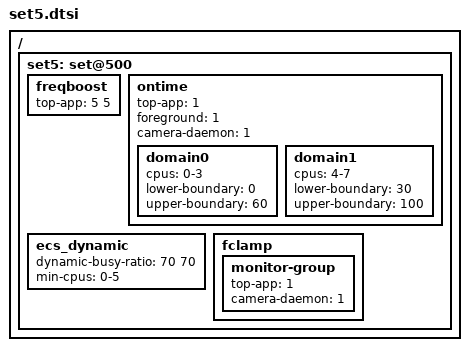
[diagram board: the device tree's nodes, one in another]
/ {
	/* camera mode - default */
	set5: set@500 {
		/* Boosting margin applied to frequency selection */
		freqboost {
			/* LIT BIG */
			top-app = <5 5>;
		};

		/* Ontime Migration */
		ontime {
			top-app		= <1>;
			foreground	= <1>;
			camera-daemon	= <1>;

			domain0 {
				cpus = "0-3";
				lower-boundary = <0>;
				upper-boundary = <60>;
			};
			domain1 {
				cpus = "4-7";
				lower-boundary = <30>;
				upper-boundary = <100>;
			};
		};

		ecs_dynamic {
			dynamic-busy-ratio = <70 70>;
			min-cpus = "0-5";
		};

		fclamp {
			monitor-group {
				top-app		= <1>;
				camera-daemon	= <1>;
			};
		};
	};
};
